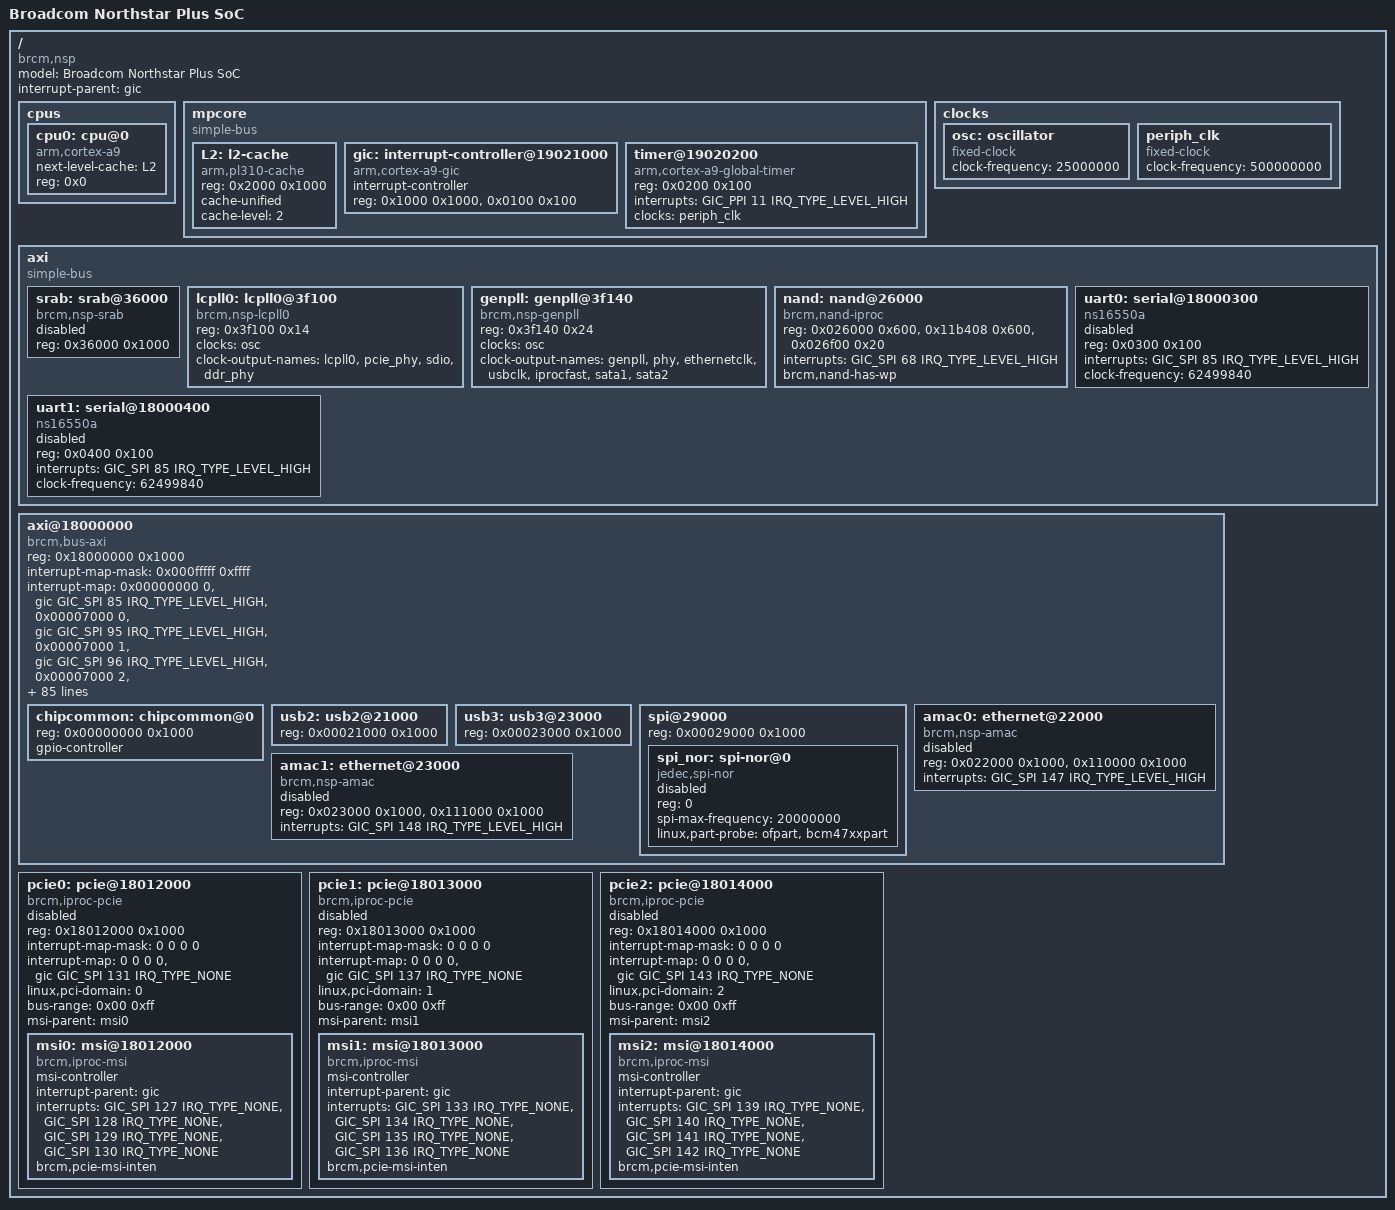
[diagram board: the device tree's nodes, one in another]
/*
 *  BSD LICENSE
 *
 *  Copyright(c) 2015 Broadcom Corporation.  All rights reserved.
 *
 *  Redistribution and use in source and binary forms, with or without
 *  modification, are permitted provided that the following conditions
 *  are met:
 *
 *    * Redistributions of source code must retain the above copyright
 *      notice, this list of conditions and the following disclaimer.
 *    * Redistributions in binary form must reproduce the above copyright
 *      notice, this list of conditions and the following disclaimer in
 *      the documentation and/or other materials provided with the
 *      distribution.
 *    * Neither the name of Broadcom Corporation nor the names of its
 *      contributors may be used to endorse or promote products derived
 *      from this software without specific prior written permission.
 *
 *  THIS SOFTWARE IS PROVIDED BY THE COPYRIGHT HOLDERS AND CONTRIBUTORS
 *  "AS IS" AND ANY EXPRESS OR IMPLIED WARRANTIES, INCLUDING, BUT NOT
 *  LIMITED TO, THE IMPLIED WARRANTIES OF MERCHANTABILITY AND FITNESS FOR
 *  A PARTICULAR PURPOSE ARE DISCLAIMED. IN NO EVENT SHALL THE COPYRIGHT
 *  OWNER OR CONTRIBUTORS BE LIABLE FOR ANY DIRECT, INDIRECT, INCIDENTAL,
 *  SPECIAL, EXEMPLARY, OR CONSEQUENTIAL DAMAGES (INCLUDING, BUT NOT
 *  LIMITED TO, PROCUREMENT OF SUBSTITUTE GOODS OR SERVICES; LOSS OF USE,
 *  DATA, OR PROFITS; OR BUSINESS INTERRUPTION) HOWEVER CAUSED AND ON ANY
 *  THEORY OF LIABILITY, WHETHER IN CONTRACT, STRICT LIABILITY, OR TORT
 *  (INCLUDING NEGLIGENCE OR OTHERWISE) ARISING IN ANY WAY OUT OF THE USE
 *  OF THIS SOFTWARE, EVEN IF ADVISED OF THE POSSIBILITY OF SUCH DAMAGE.
 */

#include <dt-bindings/interrupt-controller/arm-gic.h>
#include <dt-bindings/interrupt-controller/irq.h>

#include "skeleton.dtsi"

/ {
	compatible = "brcm,nsp";
	model = "Broadcom Northstar Plus SoC";
	interrupt-parent = <&gic>;

	cpus {   
		#address-cells = <1>;
		#size-cells = <0>;

		cpu0: cpu@0 {
				device_type = "cpu";
				compatible = "arm,cortex-a9";
				next-level-cache = <&L2>;
				reg = <0x0>;
			};
	};

	mpcore {
		compatible = "simple-bus";
		ranges = <0x00000000 0x19020000 0x00003000>;
		#address-cells = <1>;
		#size-cells = <1>;

		L2: l2-cache {
			compatible = "arm,pl310-cache";
			reg = <0x2000 0x1000>;
			cache-unified;
			cache-level = <2>;
		};

		gic: interrupt-controller@19021000 {
			compatible = "arm,cortex-a9-gic";
			#interrupt-cells = <3>;
			#address-cells = <0>;
			interrupt-controller;
			reg = <0x1000 0x1000>,
			      <0x0100 0x100>;
		};

		timer@19020200 {
			compatible = "arm,cortex-a9-global-timer";
			reg = <0x0200 0x100>;
			interrupts = <GIC_PPI 11 IRQ_TYPE_LEVEL_HIGH>;
			clocks = <&periph_clk>;
		};
	};

	clocks {
		#address-cells = <1>;
		#size-cells = <1>;
		ranges;

		osc: oscillator {
			#clock-cells = <0>;
			 compatible = "fixed-clock";
			 clock-frequency = <25000000>;
		};

		periph_clk: periph_clk {
			compatible = "fixed-clock";
			#clock-cells = <0>;
			clock-frequency = <500000000>;
		};
	};

	axi {
		compatible = "simple-bus";
		ranges = <0x00000000 0x18000000 0x0011ba08>;
		#address-cells = <1>;
		#size-cells = <1>;

		srab: srab@36000 {
			compatible = "brcm,nsp-srab";
			reg = <0x36000 0x1000>;
			#address-cells = <1>;
			#size-cells = <0>;

			status = "disabled";

			/* ports are defined in board DTS */
		};

		lcpll0: lcpll0@3f100 {
					#clock-cells = <1>;
					compatible = "brcm,nsp-lcpll0";
					reg = <0x3f100 0x14>;
					clocks = <&osc>;
					clock-output-names = "lcpll0", "pcie_phy", "sdio",
						"ddr_phy";
		};

		genpll: genpll@3f140 {
				#clock-cells = <1>;
					compatible = "brcm,nsp-genpll";
					reg = <0x3f140 0x24>;
					clocks = <&osc>;
					clock-output-names = "genpll", "phy", "ethernetclk",
						"usbclk", "iprocfast", "sata1",
						"sata2";
		};


		nand: nand@26000 {
				compatible = "brcm,nand-iproc", "brcm,brcmnand-v6.1";
				reg = <0x026000 0x600>,
						<0x11b408 0x600>,
						<0x026f00 0x20>;
				reg-names = "nand", "iproc-idm", "iproc-ext";
				interrupts = <GIC_SPI 68 IRQ_TYPE_LEVEL_HIGH>;

				#address-cells = <1>;
				#size-cells = <0>;

				brcm,nand-has-wp;
		};

		uart0: serial@18000300 {
			compatible = "ns16550a";
			reg = <0x0300 0x100>;
			interrupts = <GIC_SPI 85 IRQ_TYPE_LEVEL_HIGH>;
			clock-frequency = <62499840>;
			status = "disabled";
		};

		uart1: serial@18000400 {
			compatible = "ns16550a";
			reg = <0x0400 0x100>;
			interrupts = <GIC_SPI 85 IRQ_TYPE_LEVEL_HIGH>;
			clock-frequency = <62499840>;
			status = "disabled";
		};
	};

	axi@18000000 {
		compatible = "brcm,bus-axi";
		reg = <0x18000000 0x1000>;
		ranges = <0x00000000 0x18000000 0x00100000>;
		#address-cells = <1>;
		#size-cells = <1>;

		#interrupt-cells = <1>;
		interrupt-map-mask = <0x000fffff 0xffff>;
		interrupt-map = 
			/* ChipCommon */
			<0x00000000 0 &gic GIC_SPI 85 IRQ_TYPE_LEVEL_HIGH>,

			/* Switch Register Access Block */
			<0x00007000 0 &gic GIC_SPI 95 IRQ_TYPE_LEVEL_HIGH>,
			<0x00007000 1 &gic GIC_SPI 96 IRQ_TYPE_LEVEL_HIGH>,
			<0x00007000 2 &gic GIC_SPI 97 IRQ_TYPE_LEVEL_HIGH>,
			<0x00007000 3 &gic GIC_SPI 98 IRQ_TYPE_LEVEL_HIGH>,
			<0x00007000 4 &gic GIC_SPI 99 IRQ_TYPE_LEVEL_HIGH>,
			<0x00007000 5 &gic GIC_SPI 100 IRQ_TYPE_LEVEL_HIGH>,
			<0x00007000 6 &gic GIC_SPI 101 IRQ_TYPE_LEVEL_HIGH>,
			<0x00007000 7 &gic GIC_SPI 102 IRQ_TYPE_LEVEL_HIGH>,
			<0x00007000 8 &gic GIC_SPI 103 IRQ_TYPE_LEVEL_HIGH>,
			<0x00007000 9 &gic GIC_SPI 104 IRQ_TYPE_LEVEL_HIGH>,
			<0x00007000 10 &gic GIC_SPI 105 IRQ_TYPE_LEVEL_HIGH>,
			<0x00007000 11 &gic GIC_SPI 106 IRQ_TYPE_LEVEL_HIGH>,
			<0x00007000 12 &gic GIC_SPI 107 IRQ_TYPE_LEVEL_HIGH>,

			/* PCIe Controller 0 */
			<0x00012000 0 &gic GIC_SPI 126 IRQ_TYPE_LEVEL_HIGH>,
			<0x00012000 1 &gic GIC_SPI 127 IRQ_TYPE_LEVEL_HIGH>,
			<0x00012000 2 &gic GIC_SPI 128 IRQ_TYPE_LEVEL_HIGH>,
			<0x00012000 3 &gic GIC_SPI 129 IRQ_TYPE_LEVEL_HIGH>,
			<0x00012000 4 &gic GIC_SPI 130 IRQ_TYPE_LEVEL_HIGH>,
			<0x00012000 5 &gic GIC_SPI 131 IRQ_TYPE_LEVEL_HIGH>,

			/* PCIe Controller 1 */
			<0x00013000 0 &gic GIC_SPI 132 IRQ_TYPE_LEVEL_HIGH>,
			<0x00013000 1 &gic GIC_SPI 133 IRQ_TYPE_LEVEL_HIGH>,
			<0x00013000 2 &gic GIC_SPI 134 IRQ_TYPE_LEVEL_HIGH>,
			<0x00013000 3 &gic GIC_SPI 135 IRQ_TYPE_LEVEL_HIGH>,
			<0x00013000 4 &gic GIC_SPI 136 IRQ_TYPE_LEVEL_HIGH>,
			<0x00013000 5 &gic GIC_SPI 137 IRQ_TYPE_LEVEL_HIGH>,

			/* PCIe Controller 2 */
			<0x00014000 0 &gic GIC_SPI 138 IRQ_TYPE_LEVEL_HIGH>,
			<0x00014000 1 &gic GIC_SPI 138 IRQ_TYPE_LEVEL_HIGH>,
			<0x00014000 2 &gic GIC_SPI 140 IRQ_TYPE_LEVEL_HIGH>,
			<0x00014000 3 &gic GIC_SPI 141 IRQ_TYPE_LEVEL_HIGH>,
			<0x00014000 4 &gic GIC_SPI 142 IRQ_TYPE_LEVEL_HIGH>,
			<0x00014000 5 &gic GIC_SPI 143 IRQ_TYPE_LEVEL_HIGH>,

			/* USB 2.0 Controller */
			<0x00021000 0 &gic GIC_SPI 79 IRQ_TYPE_LEVEL_HIGH>,

			/* USB 3.0 Controller */
			<0x00023000 0 &gic GIC_SPI 80 IRQ_TYPE_LEVEL_HIGH>,

			/* Ethernet Controller 0 */
			<0x00024000 0 &gic GIC_SPI 147 IRQ_TYPE_LEVEL_HIGH>,

			/* Ethernet Controller 1 */
			<0x00025000 0 &gic GIC_SPI 148 IRQ_TYPE_LEVEL_HIGH>,

			/* Ethernet Controller 2 */
			<0x00026000 0 &gic GIC_SPI 149 IRQ_TYPE_LEVEL_HIGH>,

			/* Ethernet Controller 3 */
			<0x00027000 0 &gic GIC_SPI 150 IRQ_TYPE_LEVEL_HIGH>,

			/* NAND Controller */
			<0x00028000 0 &gic GIC_SPI 64 IRQ_TYPE_LEVEL_HIGH>,
			<0x00028000 1 &gic GIC_SPI 65 IRQ_TYPE_LEVEL_HIGH>,
			<0x00028000 2 &gic GIC_SPI 66 IRQ_TYPE_LEVEL_HIGH>,
			<0x00028000 3 &gic GIC_SPI 67 IRQ_TYPE_LEVEL_HIGH>,
			<0x00028000 4 &gic GIC_SPI 68 IRQ_TYPE_LEVEL_HIGH>,
			<0x00028000 5 &gic GIC_SPI 69 IRQ_TYPE_LEVEL_HIGH>,
			<0x00028000 6 &gic GIC_SPI 70 IRQ_TYPE_LEVEL_HIGH>,
			<0x00028000 7 &gic GIC_SPI 71 IRQ_TYPE_LEVEL_HIGH>;

		chipcommon: chipcommon@0 {
			reg = <0x00000000 0x1000>;

			gpio-controller;
			#gpio-cells = <2>;
		};

		usb2: usb2@21000 {
			reg = <0x00021000 0x1000>;

			#address-cells = <1>;
			#size-cells = <1>;
		};

		usb3: usb3@23000 {
			reg = <0x00023000 0x1000>;

			#address-cells = <1>;
			#size-cells = <1>;
		};

		spi@29000 {
			reg = <0x00029000 0x1000>;
			#address-cells = <1>;
			#size-cells = <0>;

			spi_nor: spi-nor@0 {
				compatible = "jedec,spi-nor";
				reg = <0>;
				spi-max-frequency = <20000000>;
				linux,part-probe = "ofpart", "bcm47xxpart";
				status = "disabled";
			};
		};

		amac0: ethernet@22000 {
			compatible = "brcm,nsp-amac";
			reg = <0x022000 0x1000>,
			      <0x110000 0x1000>;
			reg-names = "amac_base", "idm_base";
			interrupts = <GIC_SPI 147 IRQ_TYPE_LEVEL_HIGH>;
			status = "disabled";
		};

		amac1: ethernet@23000 {
			compatible = "brcm,nsp-amac";
			reg = <0x023000 0x1000>,
			      <0x111000 0x1000>;
			reg-names = "amac_base", "idm_base";
			interrupts = <GIC_SPI 148 IRQ_TYPE_LEVEL_HIGH>;
			status = "disabled";
		};


  /*
		gmac0: ethernet@24000 {
			reg = <0x24000 0x800>;
		};

		gmac1: ethernet@25000 {
			reg = <0x25000 0x800>;
		};

		gmac2: ethernet@26000 {
			reg = <0x26000 0x800>;
		};

		gmac3: ethernet@27000 {
			reg = <0x27000 0x800>;
		}; */
	};

        pcie0: pcie@18012000 {
                compatible = "brcm,iproc-pcie";
                reg = <0x18012000 0x1000>;

                #interrupt-cells = <1>;
                interrupt-map-mask = <0 0 0 0>;
                interrupt-map = <0 0 0 0 &gic GIC_SPI 131 IRQ_TYPE_NONE>;

                linux,pci-domain = <0>;

                bus-range = <0x00 0xff>;

                #address-cells = <3>;
                #size-cells = <2>;
                device_type = "pci";

                /* Note: The HW does not support I/O resources.  So,
                 * only the memory resource range is being specified.
                 */
                ranges = <0x82000000 0 0x08000000 0x08000000 0 0x8000000>;

                status = "disabled";

                msi-parent = <&msi0>;
                msi0: msi@18012000 {
                        compatible = "brcm,iproc-msi";
                        msi-controller;
                        interrupt-parent = <&gic>;
                        interrupts = <GIC_SPI 127 IRQ_TYPE_NONE>,
                                     <GIC_SPI 128 IRQ_TYPE_NONE>,
                                     <GIC_SPI 129 IRQ_TYPE_NONE>,
                                     <GIC_SPI 130 IRQ_TYPE_NONE>;
                        brcm,pcie-msi-inten;
                };
        };


        pcie1: pcie@18013000 {
                compatible = "brcm,iproc-pcie";
                reg = <0x18013000 0x1000>;

                #interrupt-cells = <1>;
                interrupt-map-mask = <0 0 0 0>;
                interrupt-map = <0 0 0 0 &gic GIC_SPI 137 IRQ_TYPE_NONE>;

                linux,pci-domain = <1>;

                bus-range = <0x00 0xff>;

                #address-cells = <3>;
                #size-cells = <2>;
                device_type = "pci";

                /* Note: The HW does not support I/O resources.  So,
                 * only the memory resource range is being specified.
                 */
                ranges = <0x82000000 0 0x40000000 0x40000000 0 0x8000000>;

                status = "disabled";

                msi-parent = <&msi1>;
                msi1: msi@18013000 {
                        compatible = "brcm,iproc-msi";
                        msi-controller;
                        interrupt-parent = <&gic>;
                        interrupts = <GIC_SPI 133 IRQ_TYPE_NONE>,
                                     <GIC_SPI 134 IRQ_TYPE_NONE>,
                                     <GIC_SPI 135 IRQ_TYPE_NONE>,
                                     <GIC_SPI 136 IRQ_TYPE_NONE>;
                        brcm,pcie-msi-inten;
                };
        };

        pcie2: pcie@18014000 {
                compatible = "brcm,iproc-pcie";
                reg = <0x18014000 0x1000>;

                #interrupt-cells = <1>;
                interrupt-map-mask = <0 0 0 0>;
                interrupt-map = <0 0 0 0 &gic GIC_SPI 143 IRQ_TYPE_NONE>;

                linux,pci-domain = <2>;

                bus-range = <0x00 0xff>;

                #address-cells = <3>;
                #size-cells = <2>;
                device_type = "pci";

                /* Note: The HW does not support I/O resources.  So,
                 * only the memory resource range is being specified.
                 */
                ranges = <0x82000000 0 0x48000000 0x48000000 0 0x8000000>;

                status = "disabled";

                msi-parent = <&msi2>;
                msi2: msi@18014000 {
                        compatible = "brcm,iproc-msi";
                        msi-controller;
                        interrupt-parent = <&gic>;
                        interrupts = <GIC_SPI 139 IRQ_TYPE_NONE>,
                                     <GIC_SPI 140 IRQ_TYPE_NONE>,
                                     <GIC_SPI 141 IRQ_TYPE_NONE>,
                                     <GIC_SPI 142 IRQ_TYPE_NONE>;
                        brcm,pcie-msi-inten;
                };
        };
};
